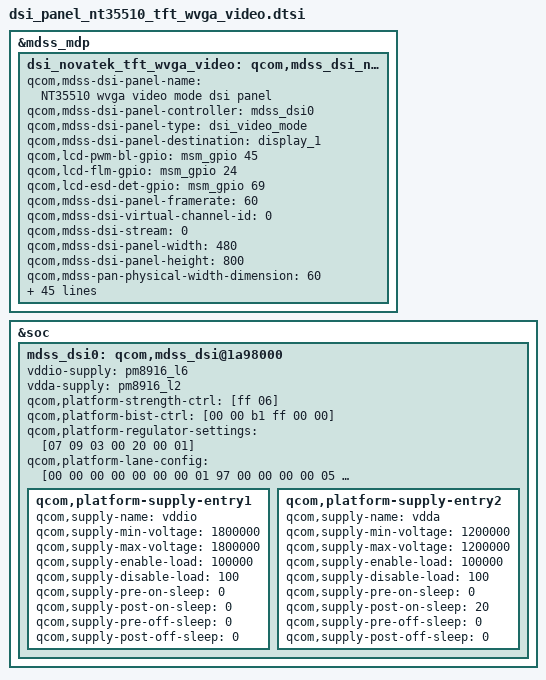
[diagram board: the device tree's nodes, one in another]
/* Copyright (c) 2013-14, Samsung Electronics Corporation. All rights reserved.
 *
 * This program is free software; you can redistribute it and/or modify
 * it under the terms of the GNU General Public License version 2 and
 * only version 2 as published by the Free Software Foundation.
 *
 * This program is distributed in the hope that it will be useful,
 * but WITHOUT ANY WARRANTY; without even the implied warranty of
 * MERCHANTABILITY or FITNESS FOR A PARTICULAR PURPOSE.  See the
 * GNU General Public License for more details.
 */

/*---------------------------------------------------------------------------
 * This file is autogenerated file using gcdb parser. Please do not edit it.
 * Update input XML file to add a new entry or update variable in this file
 * VERSION = "1.0"
 *---------------------------------------------------------------------------

 */
&mdss_mdp {
	dsi_novatek_tft_wvga_video: qcom,mdss_dsi_nt35510_wvga_video {
		qcom,mdss-dsi-panel-name = "NT35510 wvga video mode dsi panel";
		qcom,mdss-dsi-panel-controller = <&mdss_dsi0>;
		qcom,mdss-dsi-panel-type = "dsi_video_mode";
		qcom,mdss-dsi-panel-destination = "display_1";
		/*qcom,cont-splash-enabled;*/
		qcom,lcd-pwm-bl-gpio = <&msm_gpio 45 0>;
		qcom,lcd-flm-gpio = <&msm_gpio 24 0>;
		qcom,lcd-esd-det-gpio = <&msm_gpio 69 0>;
		qcom,mdss-dsi-panel-framerate = <60>;
		qcom,mdss-dsi-virtual-channel-id = <0>;
		qcom,mdss-dsi-stream = <0>;
		qcom,mdss-dsi-panel-width = <480>;
		qcom,mdss-dsi-panel-height = <800>;
              qcom,mdss-pan-physical-width-dimension = <60>; /* <Width> real size of panel in mm */
		qcom,mdss-pan-physical-height-dimension = <100>; /*<Height> real size of panel in mm */
		qcom,mdss-dsi-lp11-init;
		qcom,mdss-dsi-init-delay-us = <100>;
		qcom,mdss-dsi-h-front-porch = <32>;
		qcom,mdss-dsi-h-back-porch = <64>;
		qcom,mdss-dsi-h-pulse-width = <4>;
		qcom,mdss-dsi-h-sync-skew = <0>;
		qcom,mdss-dsi-v-back-porch = <10>;
		qcom,mdss-dsi-v-front-porch = <10>;
		qcom,mdss-dsi-v-pulse-width = <4>;
		qcom,mdss-dsi-h-left-border = <0>;
		qcom,mdss-dsi-h-right-border = <0>;
		qcom,mdss-dsi-v-top-border = <0>;
		qcom,mdss-dsi-v-bottom-border = <0>;
		qcom,mdss-dsi-bpp = <24>;
		qcom,mdss-dsi-color-order = <0>;
		qcom,mdss-dsi-underflow-color = <0xff>;
		qcom,mdss-dsi-border-color = <0>;
		qcom,mdss-dsi-dma-trigger = "trigger_sw";
		qcom,mdss-dsi-mdp-trigger = "none";
		qcom,mdss-dsi-bl-min-level = <1>;
		qcom,mdss-dsi-bl-max-level = <255>;
		qcom,mdss-dsi-bl-pmic-control-type = "bl_ctrl_pwm";
		qcom,mdss-dsi-lane-0-state;
		qcom,mdss-dsi-lane-1-state;
		qcom,mdss-dsi-bllp-eof-power-mode;
		qcom,mdss-dsi-bllp-power-mode;
		qcom,mdss-dsi-traffic-mode = "burst_mode";
		qcom,mdss-force-clk-lane-hs = <1>;
		qcom,mdss-dsi-reset-sequence = <1 20>, <0 1>, <1 120>;
		qcom,mdss-dsi-lane-map = <0>;
		qcom,mdss-dsi-h-sync-pulse = <0>;
              qcom,mdss-dsi-panel-timings = [2F 1C 12 00 40 44 16 1E 17 03 04 00];
              qcom,mdss-dsi-t-clk-pre = <0x18>;
		qcom,mdss-dsi-t-clk-post = <0x04>;
		qcom,mdss-dsi-on-command = [
						/* < Initializing Sequence(1) > */
						39 01 00 00 00 00 05 FF AA 55 25 01
						39 01 00 00 00 00 0E F8 01 02 00 20 33 13 00 40 00 00 23 02 19
						/* < Power Setting Sequence(2) > */
						39 01 00 00 00 00 06 F0 55 AA 52 08 01
						39 01 00 00 00 00 04 B6 44 44 44
						39 01 00 00 00 00 04 B0 0F 0F 0F
						39 01 00 00 00 00 04 B7 34 34 34
						39 01 00 00 00 00 04 B1 0F 0F 0F
						39 01 00 00 00 00 04 B8 34 34 34
						39 01 00 00 00 00 04 B2 02 02 02
						39 01 00 00 00 00 04 B9 24 24 24
						39 01 00 00 00 00 04 B3 06 06 06
						39 01 00 00 00 00 04 BA 14 14 14
						39 01 00 00 00 00 04 B5 08 08 08
						39 01 00 00 00 00 04 BC 00 88 00
						39 01 00 00 00 00 04 BD 00 88 00
						39 01 00 00 00 00 03 BE 00 58
						39 01 00 00 00 00 02 BF 01
						/* Gamma Control(3) */
						39 01 00 00 00 00 35
							D1 00 00 00 92 00 BF 00
							DE 00 F5 01 1B 01 39 01
							69 01 8E 01 C8 01 F5 02
							3C 02 74 02 76 02 A8 02
							DF 03 02 03 2F 03 4E 03
							76 03 93 03 B3 03 CA 03
							DD 03 FC 03 FE
						39 01 00 00 00 00 35
							D2 00 00 00 92 00 BF 00
							DE 00 F5 01 1B 01 39 01
							69 01 8E 01 C8 01 F5 02
							3C 02 74 02 76 02 A8 02
							DF 03 02 03 2F 03 4E 03
							76 03 93 03 B3 03 CA 03
							DD 03 FC 03 FE
						39 01 00 00 00 00 35
							D3 00 00 00 92 00 BF 00
							DE 00 F5 01 1B 01 39 01
							69 01 8E 01 C8 01 F5 02
							3C 02 74 02 76 02 A8 02
							DF 03 02 03 2F 03 4E 03
							76 03 93 03 B3 03 CA 03
							DD 03 FC 03 FE
						39 01 00 00 00 00 35
							D4 00 00 00 92 00 BF 00
							DE 00 F5 01 1B 01 39 01
							69 01 8E 01 C8 01 F5 02
							3C 02 74 02 76 02 A8 02
							DF 03 02 03 2F 03 4E 03
							76 03 93 03 B3 03 CA 03
							DD 03 FC 03 FE
						39 01 00 00 00 00 35
							D5 00 00 00 92 00 BF 00
							DE 00 F5 01 1B 01 39 01
							69 01 8E 01 C8 01 F5 02
							3C 02 74 02 76 02 A8 02
							DF 03 02 03 2F 03 4E 03
							76 03 93 03 B3 03 CA 03
							DD 03 FC 03 FE
						39 01 00 00 00 00 35
							D6 00 00 00 92 00 BF 00
							DE 00 F5 01 1B 01 39 01
							69 01 8E 01 C8 01 F5 02
							3C 02 74 02 76 02 A8 02
							DF 03 02 03 2F 03 4E 03
							76 03 93 03 B3 03 CA 03
							DD 03 FC 03 FE
						/* < Power Setting Sequence(4) > */
						39 01 00 00 00 00 06 F0 55 AA 52 08 00
						39 01 00 00 00 00 0C CA 00 1B 1B 1B 1B
							1B 1B 02 02 00 00
						39 01 00 00 00 00 02 B4 10
						39 01 00 00 00 00 02 B5 50
						39 01 00 00 00 00 02 B6 05
						39 01 00 00 00 00 03 B7 00 00
						39 01 00 00 00 00 05 B8 01 07 07 07
						39 01 00 00 00 00 04 BC 00 00 00
						39 01 00 00 00 00 06 C9 C0 02 50 50 50
						39 01 00 00 00 00 03 B1 FC 06
						/* Sleep out */
						05 01 00 00 B4 00 02 11 00
						/* Display on */
						05 01 00 00 78 00 02 29 00
					];
		qcom,mdss-dsi-off-command = [
						/* < Deep Sleep In Sequence > */
						39 01 00 00 10 00 02 28 00
						39 01 00 00 78 00 02 10 00
					];
		samsung,panel-manufacture-id-read-cmds = [06 01 00 00 00 00 01 da 01
							06 01 00 00 00 00 01 db 01
							06 01 00 00 00 00 01 dc 01];

		qcom,mdss-dsi-on-command-state = "dsi_lp_mode";
		qcom,mdss-dsi-off-command-state = "dsi_hs_mode";
	};
};
&soc {
	mdss_dsi0: qcom,mdss_dsi@1a98000 {
		vddio-supply = <&pm8916_l6>;
		vdda-supply = <&pm8916_l2>;
		qcom,platform-strength-ctrl = [ff 06];
		qcom,platform-bist-ctrl = [00 00 b1 ff 00 00];
		qcom,platform-regulator-settings = [07 09 03 00 20 00 01];
		qcom,platform-lane-config = [00 00 00 00 00 00 00 01 97
			00 00 00 00 05 00 00 01 97
			00 00 00 00 0a 00 00 01 97
			00 00 00 00 0f 00 00 01 97
			00 c0 00 00 00 00 00 01 bb];
		qcom,platform-supply-entry1 {
			qcom,supply-name = "vddio";
			qcom,supply-min-voltage = <1800000>;
			qcom,supply-max-voltage = <1800000>;
			qcom,supply-enable-load = <100000>;
			qcom,supply-disable-load = <100>;
			qcom,supply-pre-on-sleep = <0>;
			qcom,supply-post-on-sleep = <0>;
			qcom,supply-pre-off-sleep = <0>;
			qcom,supply-post-off-sleep = <0>;
		};
		qcom,platform-supply-entry2 {
			qcom,supply-name = "vdda";
			qcom,supply-min-voltage = <1200000>;
			qcom,supply-max-voltage = <1200000>;
			qcom,supply-enable-load = <100000>;
			qcom,supply-disable-load = <100>;
			qcom,supply-pre-on-sleep = <0>;
			qcom,supply-post-on-sleep = <20>;
			qcom,supply-pre-off-sleep = <0>;
			qcom,supply-post-off-sleep = <0>;
		};
	};
};

